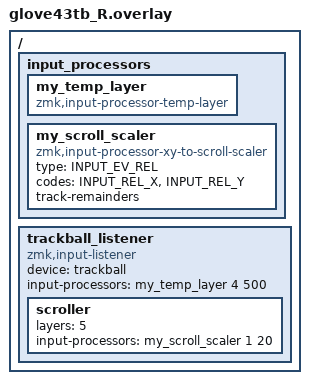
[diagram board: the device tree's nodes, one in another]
#include <zephyr/dt-bindings/input/input-event-codes.h>

/ {
    // 確実に動く定義だけをここに作ります
    input_processors {
        my_temp_layer: my_temp_layer {
            compatible = "zmk,input-processor-temp-layer";
            #input-processor-cells = <2>;
        };

        my_scroll_scaler: my_scroll_scaler {
            compatible = "zmk,input-processor-xy-to-scroll-scaler";
            #input-processor-cells = <2>;
            type = <INPUT_EV_REL>;
            codes = <INPUT_REL_X>, <INPUT_REL_Y>;
            track-remainders;
        };
    };

    trackball_listener {
        compatible = "zmk,input-listener";
        device = <&trackball>;
        
        // オートマウス
        input-processors = <&my_temp_layer 4 500>;

        // スクロール
        scroller {
            layers = <5>;
            input-processors = <&my_scroll_scaler 1 20>;
        };
    };
};
